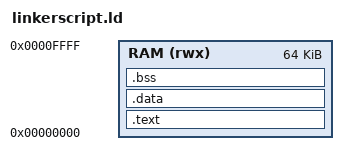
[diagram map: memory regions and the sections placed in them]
ENTRY(_start)

MEMORY {
    RAM (rwx) : ORIGIN = 0x00000000, LENGTH = 64K
}

SECTIONS {
    .text : {
        *(.text.startup)
        _svectors = .;
        *(.text.vectors)
        *(.text*)
        *(.rodata*)
        . = ALIGN(4);
    } > RAM

    .data : {
        _sdata = .;
        *(.data*)
        . = ALIGN(4);
        _edata = .;
    } > RAM AT > RAM

    .bss : {
        _sbss = .;
        *(.bss*)
        *(COMMON)
        . = ALIGN(4);
        _ebss = .;
    } > RAM

    _end = .;

    /* Define stack at the top of RAM */
    _stack_top = ORIGIN(RAM) + LENGTH(RAM);
    _stack_bottom = _stack_top - 1024; /* 1KB stack size */
}
